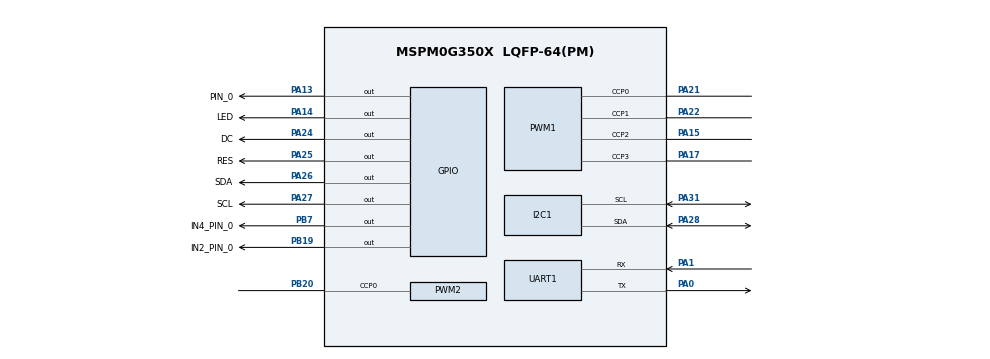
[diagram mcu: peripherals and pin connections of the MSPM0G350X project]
/**
 * @cliArgs --device "MSPM0G350X" --package "LQFP-64(PM)" --part "Default" --product "mspm0_sdk@1.30.00.03"
 * @versions {"tool":"1.19.0+3426"}
 */

/**
 * Import the modules used in this configuration.
 */
const GPIO    = scripting.addModule("/ti/driverlib/GPIO", {}, false);
const GPIO1   = GPIO.addInstance();
const GPIO2   = GPIO.addInstance();
const GPIO3   = GPIO.addInstance();
const GPIO4   = GPIO.addInstance();
const GPIO5   = GPIO.addInstance();
const I2C     = scripting.addModule("/ti/driverlib/I2C", {}, false);
const I2C1    = I2C.addInstance();
const PWM     = scripting.addModule("/ti/driverlib/PWM", {}, false);
const PWM1    = PWM.addInstance();
const PWM2    = PWM.addInstance();
const SYSCTL  = scripting.addModule("/ti/driverlib/SYSCTL");
const SYSTICK = scripting.addModule("/ti/driverlib/SYSTICK");
const UART    = scripting.addModule("/ti/driverlib/UART", {}, false);
const UART1   = UART.addInstance();

/**
 * Write custom configuration values to the imported modules.
 */
const gate7  = system.clockTree["MFCLKGATE"];
gate7.enable = true;

GPIO1.port                           = "PORTA";
GPIO1.$name                          = "LCD";
GPIO1.associatedPins.create(8);
GPIO1.associatedPins[0].$name        = "SCL";
GPIO1.associatedPins[0].initialValue = "SET";
GPIO1.associatedPins[0].pin.$assign  = "PA27";
GPIO1.associatedPins[1].$name        = "SDA";
GPIO1.associatedPins[1].initialValue = "SET";
GPIO1.associatedPins[1].pin.$assign  = "PA26";
GPIO1.associatedPins[2].$name        = "RES";
GPIO1.associatedPins[2].initialValue = "SET";
GPIO1.associatedPins[2].pin.$assign  = "PA25";
GPIO1.associatedPins[3].$name        = "DC";
GPIO1.associatedPins[3].initialValue = "SET";
GPIO1.associatedPins[3].pin.$assign  = "PA24";
GPIO1.associatedPins[4].initialValue = "SET";
GPIO1.associatedPins[4].$name        = "CS2";
GPIO1.associatedPins[5].$name        = "CS1";
GPIO1.associatedPins[6].$name        = "FSO";
GPIO1.associatedPins[7].$name        = "BLK";

const Board = scripting.addModule("/ti/driverlib/Board", {}, false);

GPIO2.$name                         = "IN2";
GPIO2.port                          = "PORTB";
GPIO2.associatedPins[0].$name       = "IN2_PIN_0";
GPIO2.associatedPins[0].pin.$assign = "PB19";

GPIO3.$name                         = "IN4";
GPIO3.port                          = "PORTB";
GPIO3.associatedPins[0].$name       = "IN4_PIN_0";
GPIO3.associatedPins[0].pin.$assign = "PB7";

GPIO4.$name                         = "GPIO";
GPIO4.associatedPins[0].$name       = "LED";
GPIO4.associatedPins[0].pin.$assign = "PA14";

GPIO5.$name                           = "MP3";
GPIO5.port                            = "PORTA";
GPIO5.associatedPins[0].$name         = "PIN_0";
GPIO5.associatedPins[0].driveStrength = "HIGH";
GPIO5.associatedPins[0].pin.$assign   = "PA13";

I2C1.$name                     = "I2C_0";
I2C1.basicEnableController     = true;
I2C1.peripheral.$assign        = "I2C0";
I2C1.peripheral.sdaPin.$assign = "PA28";
I2C1.peripheral.sclPin.$assign = "PA31";
I2C1.sdaPinConfig.$name        = "ti_driverlib_gpio_GPIOPinGeneric2";
I2C1.sclPinConfig.$name        = "ti_driverlib_gpio_GPIOPinGeneric3";

PWM1.ccIndex                            = [0,1,2,3];
PWM1.$name                              = "PWM_MOTOR2";
PWM1.timerStartTimer                    = true;
PWM1.timerCount                         = 10000;
PWM1.clockDivider                       = 8;
PWM1.clockPrescale                      = 8;
PWM1.peripheral.ccp0Pin.$assign         = "PA21";
PWM1.peripheral.ccp1Pin.$assign         = "PA22";
PWM1.peripheral.ccp2Pin.$assign         = "PA15";
PWM1.peripheral.ccp3Pin.$assign         = "PA17";
PWM1.PWM_CHANNEL_0.$name                = "ti_driverlib_pwm_PWMTimerCC0";
PWM1.PWM_CHANNEL_1.$name                = "ti_driverlib_pwm_PWMTimerCC1";
PWM1.ccp0PinConfig.direction            = scripting.forceWrite("OUTPUT");
PWM1.ccp0PinConfig.hideOutputInversion  = scripting.forceWrite(false);
PWM1.ccp0PinConfig.onlyInternalResistor = scripting.forceWrite(false);
PWM1.ccp0PinConfig.passedPeripheralType = scripting.forceWrite("Digital");
PWM1.ccp0PinConfig.$name                = "ti_driverlib_gpio_GPIOPinGeneric4";
PWM1.ccp1PinConfig.direction            = scripting.forceWrite("OUTPUT");
PWM1.ccp1PinConfig.hideOutputInversion  = scripting.forceWrite(false);
PWM1.ccp1PinConfig.onlyInternalResistor = scripting.forceWrite(false);
PWM1.ccp1PinConfig.passedPeripheralType = scripting.forceWrite("Digital");
PWM1.ccp1PinConfig.$name                = "ti_driverlib_gpio_GPIOPinGeneric5";
PWM1.PWM_CHANNEL_2.$name                = "ti_driverlib_pwm_PWMTimerCC2";
PWM1.PWM_CHANNEL_3.$name                = "ti_driverlib_pwm_PWMTimerCC3";
PWM1.ccp2PinConfig.direction            = scripting.forceWrite("OUTPUT");
PWM1.ccp2PinConfig.hideOutputInversion  = scripting.forceWrite(false);
PWM1.ccp2PinConfig.onlyInternalResistor = scripting.forceWrite(false);
PWM1.ccp2PinConfig.passedPeripheralType = scripting.forceWrite("Digital");
PWM1.ccp2PinConfig.$name                = "ti_driverlib_gpio_GPIOPinGeneric6";
PWM1.ccp3PinConfig.direction            = scripting.forceWrite("OUTPUT");
PWM1.ccp3PinConfig.hideOutputInversion  = scripting.forceWrite(false);
PWM1.ccp3PinConfig.onlyInternalResistor = scripting.forceWrite(false);
PWM1.ccp3PinConfig.passedPeripheralType = scripting.forceWrite("Digital");
PWM1.ccp3PinConfig.$name                = "ti_driverlib_gpio_GPIOPinGeneric7";

PWM2.$name                              = "PWM_MOTOR1";
PWM2.timerStartTimer                    = true;
PWM2.clockDivider                       = 8;
PWM2.timerCount                         = 40000;
PWM2.ccIndex                            = [0];
PWM2.peripheral.$assign                 = "TIMG12";
PWM2.peripheral.ccp0Pin.$assign         = "PB20";
PWM2.PWM_CHANNEL_0.$name                = "ti_driverlib_pwm_PWMTimerCC4";
PWM2.ccp0PinConfig.direction            = scripting.forceWrite("OUTPUT");
PWM2.ccp0PinConfig.hideOutputInversion  = scripting.forceWrite(false);
PWM2.ccp0PinConfig.onlyInternalResistor = scripting.forceWrite(false);
PWM2.ccp0PinConfig.passedPeripheralType = scripting.forceWrite("Digital");
PWM2.ccp0PinConfig.$name                = "ti_driverlib_gpio_GPIOPinGeneric8";

SYSCTL.forceDefaultClkConfig = true;
SYSCTL.clockTreeEn           = true;

SYSTICK.periodEnable      = true;
SYSTICK.systickEnable     = true;
SYSTICK.interruptPriority = "0";
SYSTICK.period            = 32;

UART1.$name                    = "UART_0";
UART1.uartClkSrc               = "MFCLK";
UART1.enabledInterrupts        = ["RX"];
UART1.peripheral.$assign       = "UART0";
UART1.peripheral.rxPin.$assign = "PA1";
UART1.peripheral.txPin.$assign = "PA0";
UART1.txPinConfig.$name        = "ti_driverlib_gpio_GPIOPinGeneric0";
UART1.rxPinConfig.$name        = "ti_driverlib_gpio_GPIOPinGeneric1";

/**
 * Pinmux solution for unlocked pins/peripherals. This ensures that minor changes to the automatic solver in a future
 * version of the tool will not impact the pinmux you originally saw.  These lines can be completely deleted in order to
 * re-solve from scratch.
 */
GPIO1.associatedPins[4].pin.$suggestSolution = "PA23";
GPIO1.associatedPins[5].pin.$suggestSolution = "PA18";
GPIO1.associatedPins[6].pin.$suggestSolution = "PA16";
GPIO1.associatedPins[7].pin.$suggestSolution = "PA12";
Board.peripheral.$suggestSolution            = "DEBUGSS";
Board.peripheral.swclkPin.$suggestSolution   = "PA20";
Board.peripheral.swdioPin.$suggestSolution   = "PA19";
PWM1.peripheral.$suggestSolution             = "TIMA0";
